# netx90_app register map
File version: 1.0
CPU: CM4 r0p1, little endian, MPU, FPU, 4 interrupt priority bits, 78 interrupts
Registers are 32-bit, read-write, reset 0x0 unless marked. A register's access mark holds for its fields unless they carry their own. Offsets are from the block's base; [hi:lo] are bit positions; 'fields as' and 'values as' point back to an identical list.

## hash
Base 0xFF080000
0x00 hash_din wo — Hash FIFO input: Unlike all other registers, this address can be written with DWord(32 Bit), Word(16 Bit) or Byte acccss. The FIFO controller will automatically collect data and start HASH-calculation, if enough data (complete DWords) are collected.
  [31:0] val — data bits
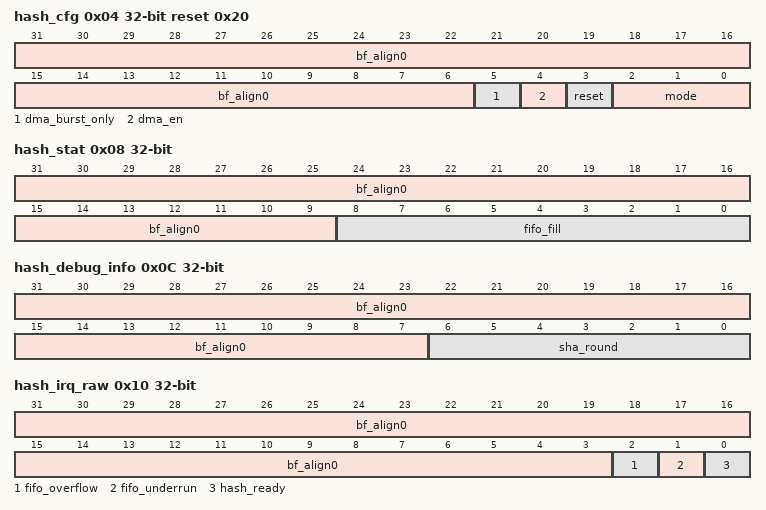
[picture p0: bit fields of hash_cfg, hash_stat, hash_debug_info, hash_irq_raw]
0x04 hash_cfg reset 0x20 (reset mask 0x3F) — Hash config register:
  [31:6] bf_align0 — bitField alignment value for aeabi compatibility
  [5] dma_burst_only — Generate DMAC burst signal only. When set to '1' the DMAC logic will only generate burst requests to the DMAC. This is to overcome limitations of the current DMA controller implementation that only accepts burst requests for DMAC controlled memory to peripheral transfers.
  [4] dma_en — Enable DMAC control signals
  [3] reset — Reset of SHA engine: After writing '1', this bit will automatically be reset. 1: reset internal registers, use this to start calculation of new hash 0: start calculation as soon as enough data in FIFO buffer
  [2:0] mode — Hash core mode 101: MD5 100: SHA2-512 011: SHA2-384 010: SHA2-256 001: SHA2-224 000: SHA1-160 Note: When changing the mode, a reset must be performed to correctly initialize the SHA/MD5 core. This can be done by setting the 'reset' bit together with the new mode or in a second access after setting the mode.
0x08 hash_stat ro (reset mask 0x1FF) — Hash status register:
  [31:9] bf_align0 — bitField alignment value for aeabi compatibility
  [8:0] fifo_fill — Fill level of FIFO in bytes (0..256)
0x0C hash_debug_info ro (reset mask 0x7F) — Hash info register:
  [31:7] bf_align0 — bitField alignment value for aeabi compatibility
  [6:0] sha_round — 7bit current state counter of the SHA core.
0x10 hash_irq_raw (reset mask 0x7) — Hash raw IRQ: Read access shows status of unmasked IRQs. IRQs are set automatically and reset by writing to this register: Write access with '1' resets the appropriate IRQ. Write access with '0' does not influence this bit.
  [31:3] bf_align0 — bitField alignment value for aeabi compatibility
  [2] fifo_overflow — input buffer was overflown, set hash_cfg-reset=1 to reset this bit.
  [1] fifo_underrun — input buffer was underrun, set hash_cfg-reset=1 to reset this bit. Note: underrun is only a theoretical FIFO status, because the hardware logic of the hash core won't fetch data from the FIFO when it's empty.
  [0] hash_ready — Hash core has finished calculation and hash value inside the registers crypt_hash[15:0] is valid. Note: This interrupt will be asserted when the hash FIFO is empty and the calculation of the last block from the FIFO has finished. The interrupt will be re-asserted after clearing as long as no new data has been fed into the FIFO or a software reset has been performed (hash_cfg-reset=1). Note: This interrupt could have got asserted in situations where the FIFO runs empty, the hash core finished the operation and new data blocks will be fed into the FIFO afterwards. In this case the IRQ will have been asserted before the very last block has been processed. In such situations it is advised to either disable the interrupt (hash_irq_mask_reset) and enable it after putting the very last data into the FIFO (hash_irq_mask_set) or to clear the IRQ once after putting the very last data and ignore any previous IRQs.
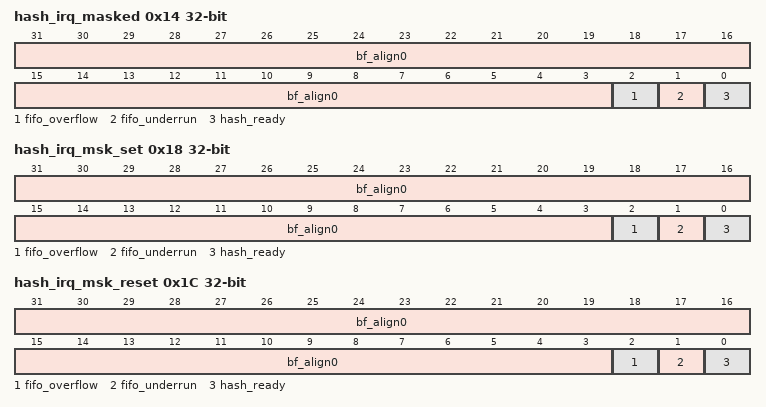
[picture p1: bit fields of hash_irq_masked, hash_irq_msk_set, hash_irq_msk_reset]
0x14 hash_irq_masked ro (reset mask 0x7) — Hash masked IRQ: Shows status of masked IRQs.
  [31:3] bf_align0 — bitField alignment value for aeabi compatibility
  [2] fifo_overflow — input buffer was overflown, set hash_cfg-reset=1 to reset this bit
  [1] fifo_underrun — input buffer was underrun, set hash_cfg-reset=1 to reset this bit
  [0] hash_ready — Hash core has finished calculation and hash value inside the registers crypt_hash[15:0] is valid
0x18 hash_irq_msk_set (reset mask 0x7) — Hash IRQ mask set: The IRQ mask enables interrupt requests for corresponding interrupt sources. As its bits might be changed by different software tasks, the IRQ mask register is not writable directly, but by set and reset masks: Write access with '1' sets interrupt mask bit. Write access with '0' does not influence this bit. Read access shows actual interrupt mask. Attention: Before activating interrupt mask, delete old pending interrupts by writing the same value to crypt_hash_irq_raw.
  fields as hash_irq_masked
0x1C hash_irq_msk_reset (reset mask 0x7) — Hash IRQ mask reset: This is the corresponding reset mask to disable interrupt requests for corresponding interrupt sources: Write access with '1' resets interrupt mask bit. Write access with '0' does not influence this bit. Read access shows actual interrupt mask.
  fields as hash_irq_masked
0x20 hash_dout0 ro — Hash value0 register
  [31:0] val — data bits 31..0
0x24 hash_dout1 ro — Hash value1 register
  [31:0] val — data bits 63..32
0x28 hash_dout2 ro — Hash value2 register
  [31:0] val — data bits 95..64
0x2C hash_dout3 ro — Hash value3 register
  [31:0] val — data bits 127..96
0x30 hash_dout4 ro — Hash value4 register
  [31:0] val — data bits 159..128
0x34 hash_dout5 ro — Hash value5 register
  [31:0] val — data bits 191..160
0x38 hash_dout6 ro — Hash value6 register
  [31:0] val — data bits 223..192
0x3C hash_dout7 ro — Hash value7 register
  [31:0] val — data bits 255..224
0x40 hash_dout8 ro — Hash value8 register
  [31:0] val — data bits 287..256
0x44 hash_dout9 ro — Hash value9 register
  [31:0] val — data bits 319..288
0x48 hash_dout10 ro — Hash value10 register
  [31:0] val — data bits 351..320
0x4C hash_dout11 ro — Hash value11 register
  [31:0] val — data bits 383..352
0x50 hash_dout12 ro — Hash value12 register
  [31:0] val — data bits 415..384
0x54 hash_dout13 ro — Hash value13 register
  [31:0] val — data bits 447..416
0x58 hash_dout14 ro — Hash value14 register
  [31:0] val — data bits 479..448
0x5C hash_dout15 ro — Hash value15 register
  [31:0] val — data bits 511..480
